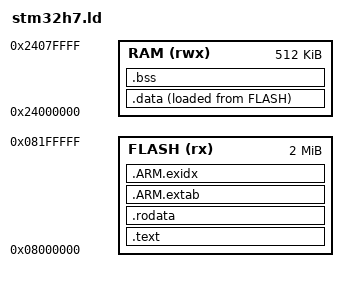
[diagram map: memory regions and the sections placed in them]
/*
 * Minimal robust linker script for STM32H7xx (Cortex-M7) HIL target builds.
 * Target: STM32H743ZI / STM32H753ZI / Pixhawk 6X
 * STM32H743: 2 MB Flash @ 0x0800_0000, 512 KB AXI SRAM @ 0x2400_0000.
 */

MEMORY
{
    FLASH (rx)  : ORIGIN = 0x08000000, LENGTH = 2048K
    RAM (rwx)   : ORIGIN = 0x24000000, LENGTH = 512K
}

ENTRY(Reset_Handler)

_estack = ORIGIN(RAM) + LENGTH(RAM);

SECTIONS
{
    .text :
    {
        . = ALIGN(4);
        KEEP(*(.vectors))
        *(.text)
        *(.text*)
        *(.glue_7)
        *(.glue_7t)
        *(.eh_frame)
        KEEP(*(.init))
        KEEP(*(.fini))
        . = ALIGN(4);
        _etext = .;
    } > FLASH

    .rodata :
    {
        . = ALIGN(4);
        *(.rodata)
        *(.rodata*)
        . = ALIGN(4);
    } > FLASH

    .ARM.extab :
    {
        *(.ARM.extab* .gnu.linkonce.armextab.*)
    } > FLASH

    .ARM.exidx :
    {
        __exidx_start = .;
        *(.ARM.exidx* .gnu.linkonce.armexidx.*)
        __exidx_end = .;
    } > FLASH

    _sidata = LOADADDR(.data);

    .data :
    {
        . = ALIGN(4);
        _sdata = .;
        *(.data)
        *(.data*)
        . = ALIGN(4);
        _edata = .;
    } > RAM AT > FLASH

    .bss :
    {
        . = ALIGN(4);
        _sbss = .;
        __bss_start__ = _sbss;
        *(.bss)
        *(.bss*)
        *(COMMON)
        . = ALIGN(4);
        _ebss = .;
        __bss_end__ = _ebss;
    } > RAM

    . = ALIGN(8);
    _end = .;
    PROVIDE(end = .);

    /DISCARD/ :
    {
        *(.comment)
        *(.ARM.attributes)
    }
}
